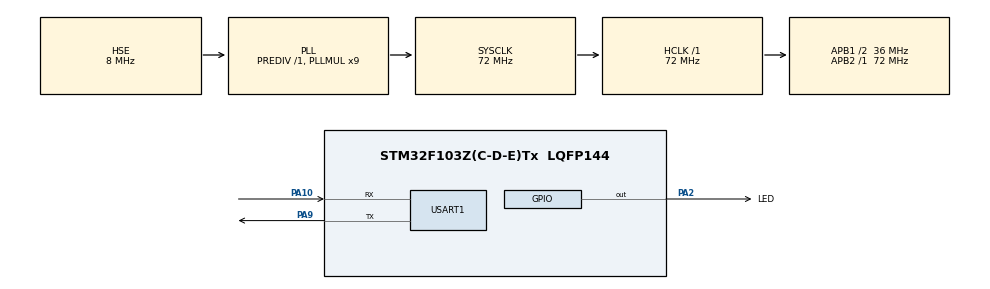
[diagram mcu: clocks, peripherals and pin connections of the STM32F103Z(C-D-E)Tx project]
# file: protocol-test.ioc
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Dma.Request0=USART1_RX
Dma.USART1_RX.0.Direction=DMA_PERIPH_TO_MEMORY
Dma.USART1_RX.0.Instance=DMA1_Channel5
Dma.USART1_RX.0.MemDataAlignment=DMA_MDATAALIGN_BYTE
Dma.USART1_RX.0.MemInc=DMA_MINC_ENABLE
Dma.USART1_RX.0.Mode=DMA_NORMAL
Dma.USART1_RX.0.PeriphDataAlignment=DMA_PDATAALIGN_BYTE
Dma.USART1_RX.0.PeriphInc=DMA_PINC_DISABLE
Dma.USART1_RX.0.Priority=DMA_PRIORITY_LOW
Mcu.Family=STM32F1
Mcu.Name=STM32F103Z(C-D-E)Tx
Mcu.Package=LQFP144
NVIC.DMA1_Channel5_IRQn=true\:0\:0\:false\:false\:true\:false\:true
NVIC.PriorityGroup=NVIC_PRIORITYGROUP_4
NVIC.USART1_IRQn=true\:0\:0\:false\:false\:true\:true\:true
OSC_IN.Mode=HSE-External-Oscillator
OSC_IN.Signal=RCC_OSC_IN
OSC_OUT.Mode=HSE-External-Oscillator
OSC_OUT.Signal=RCC_OSC_OUT
PA10.Mode=Asynchronous
PA10.Signal=USART1_RX
PA13.Mode=Serial_Wire
PA13.Signal=SYS_JTMS-SWDIO
PA14.Mode=Serial_Wire
PA14.Signal=SYS_JTCK-SWCLK
PA2.GPIO_Label=LED
PA2.Signal=GPIO_Output
PA9.Mode=Asynchronous
PA9.Signal=USART1_TX
ProjectManager.HeapSize=0x200
ProjectManager.StackSize=0x400
ProjectManager.TargetToolchain=MDK-ARM V5.27
RCC.AHBFreq_Value=72000000
RCC.APB1CLKDivider=RCC_HCLK_DIV2
RCC.APB1Freq_Value=36000000
RCC.APB1TimFreq_Value=72000000
RCC.APB2Freq_Value=72000000
RCC.APB2TimFreq_Value=72000000
RCC.HCLKFreq_Value=72000000
RCC.PLLMUL=RCC_PLL_MUL9
RCC.PLLSourceVirtual=RCC_PLLSOURCE_HSE
RCC.SYSCLKFreq_VALUE=72000000
RCC.SYSCLKSource=RCC_SYSCLKSOURCE_PLLCLK
RCC.USBFreq_Value=72000000
USART1.VirtualMode=VM_ASYNC
board=custom

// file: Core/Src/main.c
/* USER CODE BEGIN Header */
/**
  ******************************************************************************
  * @file           : main.c
  * @brief          : Main program body
  ******************************************************************************
  * @attention
  *
  * <h2><center>&copy; Copyright (c) 2021 STMicroelectronics.
  * All rights reserved.</center></h2>
  *
  * This software component is licensed by ST under BSD 3-Clause license,
  * the "License"; You may not use this file except in compliance with the
  * License. You may obtain a copy of the License at:
  *                        opensource.org/licenses/BSD-3-Clause
  *
  ******************************************************************************
  */
/* USER CODE END Header */
#include "main.h"
#include "dma.h"
#include "usart.h"
#include "gpio.h"

/* USER CODE BEGIN Includes */
#include "ring_buffer.h"
#include "debug.h"
#include "protocol_analysis.h"
#include "string.h"
#include "rtlist.h"
/* USER CODE END Includes */

/* USER CODE BEGIN PTD */
typedef struct
{
	uint8_t age;
	uint8_t name[20];
	rt_list_t node;
}Person;

/* USER CODE END PTD */

/* USER CODE BEGIN PD */

#define CACHE_LEN 200
/* USER CODE END PD */

/* USER CODE BEGIN PV */
ring_buffer ring_buf;
uint8_t data_cache[CACHE_LEN];
/* USER CODE END PV */

void SystemClock_Config(void);

int main(void)
{
  /* USER CODE BEGIN 1 */
	uint8_t num;
	uint8_t data[200];
	uint8_t tx_buf[200];
	message_head *msg_head;
	sk_buff skb;
	uint8_t *data_p;
  /* USER CODE END 1 */

  /* MCU Configuration--------------------------------------------------------*/

  /* Reset of all peripherals, Initializes the Flash interface and the Systick. */
  HAL_Init();

  /* Configure the system clock */
  SystemClock_Config();

  /* Initialize all configured peripherals */
  MX_GPIO_Init();
  MX_DMA_Init();
  MX_USART1_UART_Init();
  /* USER CODE BEGIN 2 */
HAL_UART_Receive_DMA(&huart1,rx_buffer,BUFFER_SIZE);
Ring_Buffer_Init(&ring_buf,data_cache,CACHE_LEN);

  /* USER CODE END 2 */

  /* Infinite loop */
  /* USER CODE BEGIN WHILE */
  while (1)
  {
	  HAL_Delay(1000);
	  HAL_GPIO_TogglePin(LED_GPIO_Port,LED_Pin);

	  uint8_t **buf = &skb.end;

	  sk_buff *skb2 = rt_container_of(buf,sk_buff,end);

	  rt_list_t person = RT_LIST_OBJECT_INIT(person);

	  Person p1 = {20,"yi"};
	  Person p2 = {30,"er"};
	  Person p3 = {25,"san"};

	  rt_list_insert_after(&person,&p1.node);
	  rt_list_insert_after(&person,&p2.node);
	  rt_list_insert_after(&person,&p3.node);

	  Person *p;
	  rt_list_for_each_entry_reverse(p,&person,node)
	  {
		myprintf("age is %d,name is %s\r\n",p->age,(char *)(p->name));
	  }

	  while((num = if_find_frame_end(&ring_buf,data)))
	  {
		  msg_head = (message_head *)data;
		  if(!(msg_head->bigin == HEAD && 1))//判断帧头是否正确、校验值是否正确或者通信地址是否正确
			continue;

		  switch(msg_head->command)
		  {
			  case 0x00:
				  myprintf("No.0 command!\r\n");
			  break;

			  case 0x01:
				  door_control(msg_head->subCmd,msg_head->data,msg_head->dataLength);
			  break;

			  case 0x02:
				sk_buff_init(&skb,tx_buf,200);
				skb_reserve(&skb,50);
			  smd_door door = {0x11,0x22};
			  if((data_p = skb_put(&skb,2)) != NULL)
			  {
				memcpy(data_p,&door,sizeof(smd_door));
			  }

			  message_head head = {0xaabb,0x22,0x33,0x11223344,0x55,0x66,0x77,0x88};
			  if((data_p = skb_push(&skb,sizeof(message_head))) != NULL)
			  {
				memcpy(data_p,&head,sizeof(message_head));
			  }

			  frame_end end = {0x99,0xbbaa};
			  if((data_p = skb_put(&skb,sizeof(frame_end))) != NULL)
			  {
				memcpy(data_p,&end,sizeof(frame_end));
			  }
			  HAL_UART_Transmit(&huart1,skb.data,skb.data_len,1000);

			  break;

			  default:
				break;
		  }

		  debug_printf("num is %d\r\n",num);
		  debug_printf("head is %x\r\n",msg_head->bigin);
		  debug_printf("version is %d\r\n",msg_head->version);
		  debug_printf("msgid is %x\r\n",msg_head->msgID);
		  debug_printf("time is %x\r\n",msg_head->timePoint);
		  debug_printf("msgtype is %d\r\n",msg_head->msgType);
		  debug_printf("command is %d\r\n",msg_head->command);
		  debug_printf("subcmd is %d\r\n",msg_head->subCmd);
		  debug_printf("datalength is %d\r\n",msg_head->dataLength);

	  }

//	  myprintf("last num is %d\r\n",Ring_Buffer_Get_Lenght(&ring_buf));

//	  HAL_UART_Transmit(&huart1,"hello",5,1000);

    /* USER CODE END WHILE */

  }
}

void SystemClock_Config(void)
{
  RCC_OscInitTypeDef RCC_OscInitStruct = {0};
  RCC_ClkInitTypeDef RCC_ClkInitStruct = {0};

  /** Initializes the RCC Oscillators according to the specified parameters
  * in the RCC_OscInitTypeDef structure.
  */
  RCC_OscInitStruct.OscillatorType = RCC_OSCILLATORTYPE_HSE;
  RCC_OscInitStruct.HSEState = RCC_HSE_ON;
  RCC_OscInitStruct.HSEPredivValue = RCC_HSE_PREDIV_DIV1;
  RCC_OscInitStruct.HSIState = RCC_HSI_ON;
  RCC_OscInitStruct.PLL.PLLState = RCC_PLL_ON;
  RCC_OscInitStruct.PLL.PLLSource = RCC_PLLSOURCE_HSE;
  RCC_OscInitStruct.PLL.PLLMUL = RCC_PLL_MUL9;
  if (HAL_RCC_OscConfig(&RCC_OscInitStruct) != HAL_OK)
  {
    Error_Handler();
  }
  /** Initializes the CPU, AHB and APB buses clocks
  */
  RCC_ClkInitStruct.ClockType = RCC_CLOCKTYPE_HCLK|RCC_CLOCKTYPE_SYSCLK
                              |RCC_CLOCKTYPE_PCLK1|RCC_CLOCKTYPE_PCLK2;
  RCC_ClkInitStruct.SYSCLKSource = RCC_SYSCLKSOURCE_PLLCLK;
  RCC_ClkInitStruct.AHBCLKDivider = RCC_SYSCLK_DIV1;
  RCC_ClkInitStruct.APB1CLKDivider = RCC_HCLK_DIV2;
  RCC_ClkInitStruct.APB2CLKDivider = RCC_HCLK_DIV1;

  if (HAL_RCC_ClockConfig(&RCC_ClkInitStruct, FLASH_LATENCY_2) != HAL_OK)
  {
    Error_Handler();
  }
}

/* USER CODE BEGIN 4 */
void HAL_UART_RxCpltCallback(UART_HandleTypeDef *huart)
{
	if(huart1.Instance == USART1)
	{
	    rx_cpt_nums = BUFFER_SIZE - hdma_usart1_rx.Instance->CNDTR;
//		HAL_UART_Transmit(&huart1,rx_buffer,rx_cpt_nums,1000);

		Ring_Buffer_Write_String(&ring_buf,rx_buffer,rx_cpt_nums);

		HAL_UART_Receive_DMA(&huart1,rx_buffer,BUFFER_SIZE);
	}
}
/* USER CODE END 4 */

void Error_Handler(void)
{
}

/************************ (C) COPYRIGHT STMicroelectronics *****END OF FILE****/
